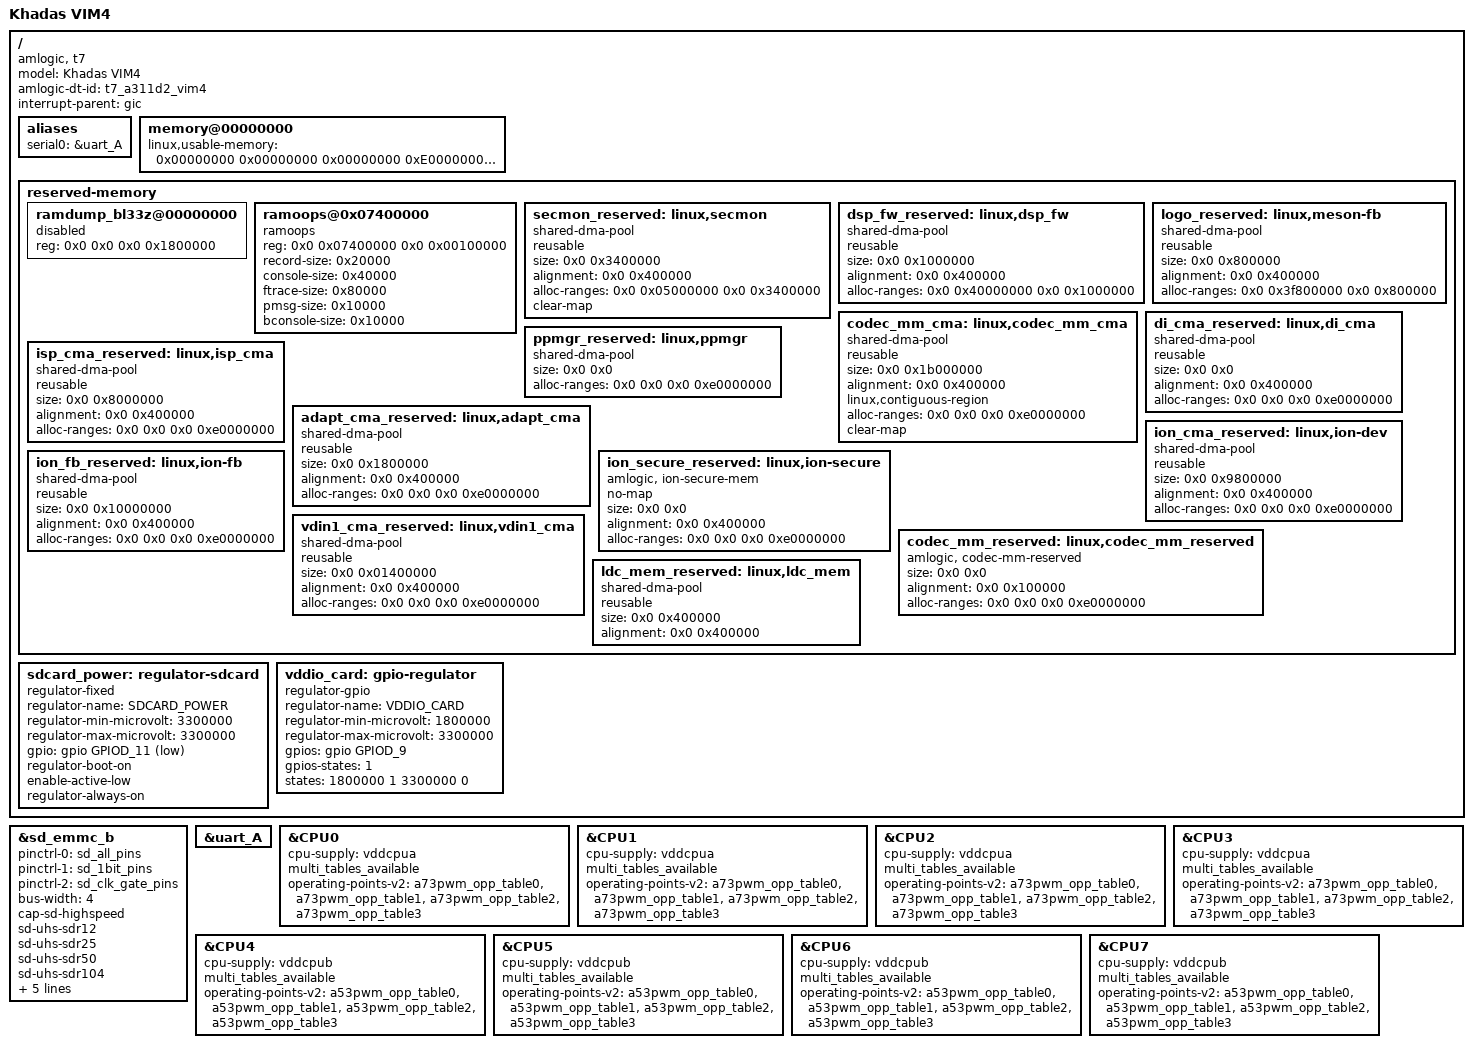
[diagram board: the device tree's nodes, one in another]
// SPDX-License-Identifier: (GPL-2.0+ OR MIT)
/*
 * Copyright (c) 2022 Wesion, Inc. All rights reserved.
 */

/dts-v1/;

#include "mesont7.dtsi"

/ {
	model = "Khadas VIM4";
	amlogic-dt-id = "t7_a311d2_vim4";
	compatible = "amlogic, t7";
	interrupt-parent = <&gic>;
	#address-cells = <2>;
	#size-cells = <2>;

	aliases {
		serial0 = &uart_A;
	};

	memory@00000000 {
		device_type = "memory";
		linux,usable-memory = <0x00000000 0x00000000 0x00000000 0xE0000000
			0x00000001 0x00000000 0x00000001 0x20000000>;
	};

	reserved-memory {
		#address-cells = <2>;
		#size-cells = <2>;
		ranges;

		ramdump_bl33z@00000000 {
			reg = <0x0 0x0 0x0 0x1800000>; /* 0 ~ 24M */
			status = "disabled";
		};

		/* global autoconfigured region for contiguous allocations */
		ramoops@0x07400000 {
			compatible = "ramoops";
			reg = <0x0 0x07400000 0x0 0x00100000>;
			record-size = <0x20000>;
			console-size = <0x40000>;
			ftrace-size = <0x80000>;
			pmsg-size = <0x10000>;
			bconsole-size = <0x10000>;
		};

		secmon_reserved:linux,secmon {
			compatible = "shared-dma-pool";
			reusable;
			size = <0x0 0x3400000>;
			alignment = <0x0 0x400000>;
			alloc-ranges = <0x0 0x05000000 0x0 0x3400000>;
			clear-map;
		};

		dsp_fw_reserved:linux,dsp_fw {
			compatible = "shared-dma-pool";
			reusable;
			size = <0x0 0x1000000>;
			alignment = <0x0 0x400000>;
			alloc-ranges = <0x0 0x40000000 0x0 0x1000000>;
		};

		logo_reserved:linux,meson-fb {
			compatible = "shared-dma-pool";
			reusable;
			size = <0x0 0x800000>;
			alignment = <0x0 0x400000>;
			alloc-ranges = <0x0 0x3f800000 0x0 0x800000>;
		};

		codec_mm_cma:linux,codec_mm_cma {
			compatible = "shared-dma-pool";
			reusable;
			/* ion_codec_mm max can alloc size 80M*/
			size = <0x0 0x1b000000>;
			alignment = <0x0 0x400000>;
			linux,contiguous-region;
			alloc-ranges = <0x0 0x0 0x0 0xe0000000>;
			clear-map;
		};

		/*di CMA pool */
		di_cma_reserved:linux,di_cma {
			compatible = "shared-dma-pool";
			reusable;
			/* buffer_size = 3621952(yuv422 8bit)
			 *  | 4736064(yuv422 10bit)
			 *  | 4074560(yuv422 10bit full pack mode)
			 * 10x3621952=34.6M(0x23) support 8bit
			 * 10x4736064=45.2M(0x2e) support 12bit
			 * 10x4074560=40M(0x28) support 10bit
			 */
			size = <0x0 0x0>;
			alignment = <0x0 0x400000>;
			alloc-ranges = <0x0 0x0 0x0 0xe0000000>;
		};

		/*  POST PROCESS MANAGER */
		ppmgr_reserved:linux,ppmgr {
			compatible = "shared-dma-pool";
			size = <0x0 0x0>;
			alloc-ranges = <0x0 0x0 0x0 0xe0000000>;
		};

		isp_cma_reserved:linux,isp_cma {
			compatible = "shared-dma-pool";
			reusable;
			status = "okay";
			size = <0x0 0x8000000>;
			alignment = <0x0 0x400000>;
			alloc-ranges = <0x0 0x0 0x0 0xe0000000>;
		};

		adapt_cma_reserved:linux,adapt_cma {
			compatible = "shared-dma-pool";
			reusable;
			status = "okay";
			size = <0x0 0x1800000>;
			alignment = <0x0 0x400000>;
			alloc-ranges = <0x0 0x0 0x0 0xe0000000>;
		};

		ion_cma_reserved:linux,ion-dev {
			compatible = "shared-dma-pool";
			reusable;
			size = <0x0 0x9800000>;
			alignment = <0x0 0x400000>;
			alloc-ranges = <0x0 0x0 0x0 0xe0000000>;
		};
		/* secure ion for gpu,advice size is 0x8000000 */
		ion_secure_reserved:linux,ion-secure {
			compatible = "amlogic, ion-secure-mem";
			no-map;
			size = <0x0 0x0>;
			alignment = <0x0 0x400000>;
			alloc-ranges = <0x0 0x0 0x0 0xe0000000>;
		};
		ion_fb_reserved:linux,ion-fb {
			compatible = "shared-dma-pool";
			reusable;
			/* 1920x1080x4x3 round up 4M align */
			size = <0x0 0x10000000>;
			alignment = <0x0 0x400000>;
			alloc-ranges = <0x0 0x0 0x0 0xe0000000>;
		};
		/* codec shared reserved */
		codec_mm_reserved:linux,codec_mm_reserved {
			compatible = "amlogic, codec-mm-reserved";
			size = <0x0 0x0>;
			alignment = <0x0 0x100000>;
			alloc-ranges = <0x0 0x0 0x0 0xe0000000>;
			//no-map;
		};

		/*  vdin1 CMA pool */
		vdin1_cma_reserved:linux,vdin1_cma {
			compatible = "shared-dma-pool";
			reusable;
			/* up to 1920x1080 yuv422 8bit and 5 buffers
			 * 1920x1080x2x5 = 20 M
			 */
			size = <0x0 0x01400000>;
			alignment = <0x0 0x400000>;
			alloc-ranges = <0x0 0x0 0x0 0xe0000000>;
		};

		ldc_mem_reserved:linux,ldc_mem {
			compatible = "shared-dma-pool";
			reusable;
			size = <0x0 0x400000>;
			alignment = <0x0 0x400000>;
		};
	};

	sdcard_power: regulator-sdcard {
			compatible = "regulator-fixed";
			regulator-name = "SDCARD_POWER";
			regulator-min-microvolt = <3300000>;
			regulator-max-microvolt = <3300000>;
			gpio = <&gpio GPIOD_11 GPIO_ACTIVE_LOW>;
			regulator-boot-on;
			enable-active-low;
			regulator-always-on;
	};

	vddio_card: gpio-regulator {
			compatible = "regulator-gpio";
			regulator-name = "VDDIO_CARD";
			regulator-min-microvolt = <1800000>;
			regulator-max-microvolt = <3300000>;
			gpios = <&gpio GPIOD_9 GPIO_ACTIVE_HIGH>;
			gpios-states = <1>;
			states = <1800000 1
					3300000 0>;
	};
};

/* SD card */
&sd_emmc_b {
	status = "okay";
	pinctrl-0 = <&sd_all_pins>;
	pinctrl-1 = <&sd_1bit_pins>;
	pinctrl-2 = <&sd_clk_gate_pins>;
	pinctrl-names = "sd_default",
			"sd_1bit_pins",
			"clk-gate";
	bus-width = <4>;
	cap-sd-highspeed;
	sd-uhs-sdr12;
	sd-uhs-sdr25;
	sd-uhs-sdr50;
	sd-uhs-sdr104;
	max-frequency = <200000000>;

	disable-wp;

	cd-gpios = <&gpio GPIOC_6 GPIO_ACTIVE_HIGH>;
	//dat1-gpios = <&gpio GPIOC_1 GPIO_ACTIVE_HIGH>;
	vmmc-supply = <&sdcard_power>;
	vqmmc-supply = <&vddio_card>;
};

&uart_A {
	status = "okay";
};

&CPU0 {
	cpu-supply = <&vddcpua>;
	multi_tables_available;
	operating-points-v2 = <&a73pwm_opp_table0>,
		<&a73pwm_opp_table1>,
		<&a73pwm_opp_table2>,
		<&a73pwm_opp_table3>;
};

&CPU1 {
	cpu-supply = <&vddcpua>;
	multi_tables_available;
	operating-points-v2 = <&a73pwm_opp_table0>,
		<&a73pwm_opp_table1>,
		<&a73pwm_opp_table2>,
		<&a73pwm_opp_table3>;
};

&CPU2 {
	cpu-supply = <&vddcpua>;
	multi_tables_available;
	operating-points-v2 = <&a73pwm_opp_table0>,
		<&a73pwm_opp_table1>,
		<&a73pwm_opp_table2>,
		<&a73pwm_opp_table3>;
};

&CPU3 {
	cpu-supply = <&vddcpua>;
	multi_tables_available;
	operating-points-v2 = <&a73pwm_opp_table0>,
		<&a73pwm_opp_table1>,
		<&a73pwm_opp_table2>,
		<&a73pwm_opp_table3>;
};

&CPU4 {
	cpu-supply = <&vddcpub>;
	multi_tables_available;
	operating-points-v2 = <&a53pwm_opp_table0>,
		<&a53pwm_opp_table1>,
		<&a53pwm_opp_table2>,
		<&a53pwm_opp_table3>;
};

&CPU5 {
	cpu-supply = <&vddcpub>;
	multi_tables_available;
	operating-points-v2 = <&a53pwm_opp_table0>,
		<&a53pwm_opp_table1>,
		<&a53pwm_opp_table2>,
		<&a53pwm_opp_table3>;
};

&CPU6 {
	cpu-supply = <&vddcpub>;
	multi_tables_available;
	operating-points-v2 = <&a53pwm_opp_table0>,
		<&a53pwm_opp_table1>,
		<&a53pwm_opp_table2>,
		<&a53pwm_opp_table3>;
};

&CPU7 {
	cpu-supply = <&vddcpub>;
	multi_tables_available;
	operating-points-v2 = <&a53pwm_opp_table0>,
		<&a53pwm_opp_table1>,
		<&a53pwm_opp_table2>,
		<&a53pwm_opp_table3>;
};

